# f28e12x_sync_soc_regs register map
Vendor: Texas Instruments
Peripheral module from a debugger description file (folder C2000).
Address unit: 16 bits
Registers are 32-bit, read-write, no defined reset value unless marked. A register's access mark holds for its fields unless they carry their own. Offsets are as the file gives them; lines under a group give offsets from that group; [hi:lo] are bit positions; {n}, {i} and the like mark numbered series; 'fields as' and 'values as' point back to an identical list; <NAME> marks a mode.

## SYNC_SOC_REGS — SYNC SOC Registers
0x00 SYNCSELECT — Sync Input and Output Select Register
  [28:24] SYNCOUT — Select EXT Syncout Source
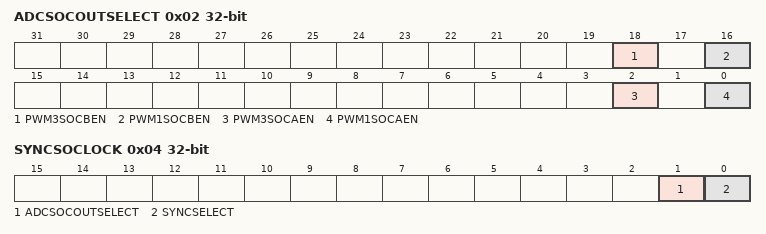
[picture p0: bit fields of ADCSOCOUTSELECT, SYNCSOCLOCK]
0x02 ADCSOCOUTSELECT — External ADCSOC Select Register
  [18] PWM3SOCBEN — PWM3SOCBEN Enable for ADCSOCBOn
  [16] PWM1SOCBEN — PWM1SOCBEN Enable for ADCSOCBOn
  [2] PWM3SOCAEN — PWM3SOCAEN Enable for ADCSOCAOn
  [0] PWM1SOCAEN — PWM1SOCAEN Enable for ADCSOCAOn
0x04 SYNCSOCLOCK — SYNCSEL and EXTADCSOC Select Lock register
  [1] ADCSOCOUTSELECT — ADCSOCOUTSELECT Register Lock bit
  [0] SYNCSELECT — SYNCSEL Register Lock bit
